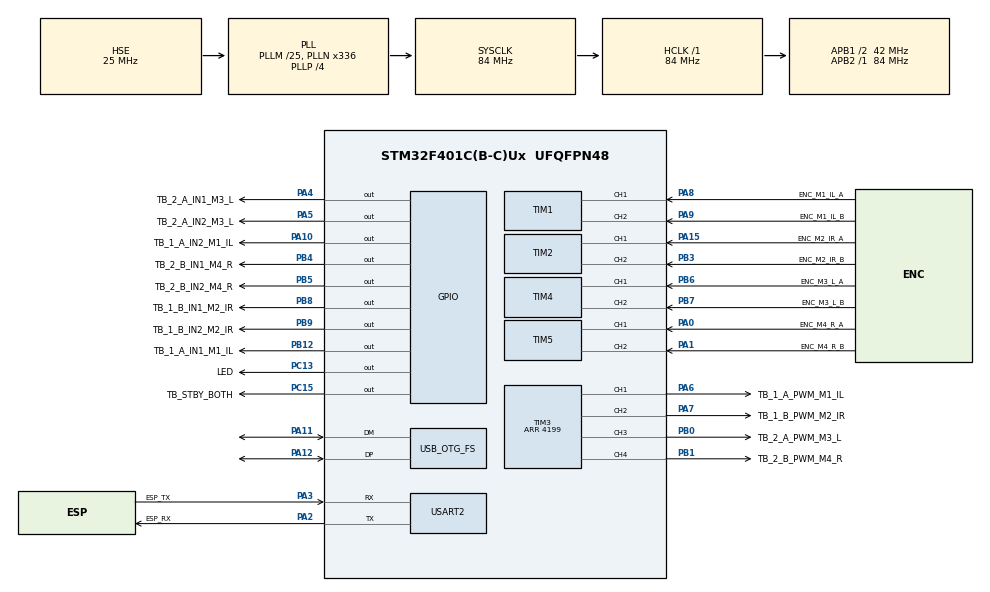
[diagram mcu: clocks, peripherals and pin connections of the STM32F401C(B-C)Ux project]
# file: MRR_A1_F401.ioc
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Dma.Request0=USART2_RX
Dma.Request1=USART2_TX
Dma.USART2_RX.0.Direction=DMA_PERIPH_TO_MEMORY
Dma.USART2_RX.0.FIFOMode=DMA_FIFOMODE_DISABLE
Dma.USART2_RX.0.Instance=DMA1_Stream5
Dma.USART2_RX.0.MemDataAlignment=DMA_MDATAALIGN_BYTE
Dma.USART2_RX.0.MemInc=DMA_MINC_ENABLE
Dma.USART2_RX.0.Mode=DMA_CIRCULAR
Dma.USART2_RX.0.PeriphDataAlignment=DMA_PDATAALIGN_BYTE
Dma.USART2_RX.0.PeriphInc=DMA_PINC_DISABLE
Dma.USART2_RX.0.Priority=DMA_PRIORITY_LOW
Dma.USART2_TX.1.Direction=DMA_MEMORY_TO_PERIPH
Dma.USART2_TX.1.FIFOMode=DMA_FIFOMODE_DISABLE
Dma.USART2_TX.1.Instance=DMA1_Stream6
Dma.USART2_TX.1.MemDataAlignment=DMA_MDATAALIGN_BYTE
Dma.USART2_TX.1.MemInc=DMA_MINC_ENABLE
Dma.USART2_TX.1.Mode=DMA_NORMAL
Dma.USART2_TX.1.PeriphDataAlignment=DMA_PDATAALIGN_BYTE
Dma.USART2_TX.1.PeriphInc=DMA_PINC_DISABLE
Dma.USART2_TX.1.Priority=DMA_PRIORITY_LOW
Mcu.Family=STM32F4
Mcu.Name=STM32F401C(B-C)Ux
Mcu.Package=UFQFPN48
NVIC.DMA1_Stream5_IRQn=true\:2\:0\:true\:false\:true\:false\:true\:true
NVIC.DMA1_Stream6_IRQn=true\:2\:0\:true\:false\:true\:false\:true\:true
NVIC.OTG_FS_IRQn=true\:3\:0\:true\:false\:true\:true\:true\:true
NVIC.PriorityGroup=NVIC_PRIORITYGROUP_4
NVIC.TIM1_UP_TIM10_IRQn=true\:1\:0\:true\:false\:true\:true\:true\:true
NVIC.USART2_IRQn=true\:2\:0\:true\:false\:true\:false\:true\:true
PA0-WKUP.GPIO_Label=ENC_M4_R_A
PA0-WKUP.GPIO_PuPd=GPIO_PULLUP
PA0-WKUP.Signal=S_TIM5_CH1
PA1.GPIO_Label=ENC_M4_R_B
PA1.GPIO_PuPd=GPIO_PULLUP
PA1.Signal=S_TIM5_CH2
PA10.GPIO_Label=TB_1_A_IN2_M1_IL
PA10.Signal=GPIO_Output
PA11.Mode=Device_Only
PA11.Signal=USB_OTG_FS_DM
PA12.Mode=Device_Only
PA12.Signal=USB_OTG_FS_DP
PA13.Mode=Serial_Wire
PA13.Signal=SYS_JTMS-SWDIO
PA14.Mode=Serial_Wire
PA14.Signal=SYS_JTCK-SWCLK
PA15.GPIO_Label=ENC_M2_IR_A
PA15.GPIO_PuPd=GPIO_PULLUP
PA15.Signal=S_TIM2_CH1_ETR
PA2.GPIO_Label=ESP_RX
PA2.Mode=Asynchronous
PA2.Signal=USART2_TX
PA3.GPIO_Label=ESP_TX
PA3.GPIO_PuPd=GPIO_PULLUP
PA3.Mode=Asynchronous
PA3.Signal=USART2_RX
PA4.GPIO_Label=TB_2_A_IN1_M3_L
PA4.Signal=GPIO_Output
PA5.GPIO_Label=TB_2_A_IN2_M3_L
PA5.Signal=GPIO_Output
PA6.GPIO_Label=TB_1_A_PWM_M1_IL
PA6.Signal=S_TIM3_CH1
PA7.GPIO_Label=TB_1_B_PWM_M2_IR
PA7.Signal=S_TIM3_CH2
PA8.GPIO_Label=ENC_M1_IL_A
PA8.GPIO_PuPd=GPIO_PULLUP
PA8.Signal=S_TIM1_CH1
PA9.GPIO_Label=ENC_M1_IL_B
PA9.GPIO_PuPd=GPIO_PULLUP
PA9.Signal=S_TIM1_CH2
PB0.GPIO_Label=TB_2_A_PWM_M3_L
PB0.Signal=S_TIM3_CH3
PB1.GPIO_Label=TB_2_B_PWM_M4_R
PB1.Signal=S_TIM3_CH4
PB12.GPIO_Label=TB_1_A_IN1_M1_IL
PB12.Signal=GPIO_Output
PB3.GPIO_Label=ENC_M2_IR_B
PB3.GPIO_PuPd=GPIO_PULLUP
PB3.Signal=S_TIM2_CH2
PB4.GPIO_Label=TB_2_B_IN1_M4_R
PB4.Signal=GPIO_Output
PB5.GPIO_Label=TB_2_B_IN2_M4_R
PB5.Signal=GPIO_Output
PB6.GPIO_Label=ENC_M3_L_A
PB6.GPIO_PuPd=GPIO_PULLUP
PB6.Signal=S_TIM4_CH1
PB7.GPIO_Label=ENC_M3_L_B
PB7.GPIO_PuPd=GPIO_PULLUP
PB7.Signal=S_TIM4_CH2
PB8.GPIO_Label=TB_1_B_IN1_M2_IR
PB8.Signal=GPIO_Output
PB9.GPIO_Label=TB_1_B_IN2_M2_IR
PB9.Signal=GPIO_Output
PC13-ANTI_TAMP.GPIO_Label=LED
PC13-ANTI_TAMP.Signal=GPIO_Output
PC15-OSC32_OUT.GPIO_Label=TB_STBY_BOTH
PC15-OSC32_OUT.Signal=GPIO_Output
PH0\ -\ OSC_IN.Mode=HSE-External-Oscillator
PH0\ -\ OSC_IN.Signal=RCC_OSC_IN
PH1\ -\ OSC_OUT.Mode=HSE-External-Oscillator
PH1\ -\ OSC_OUT.Signal=RCC_OSC_OUT
ProjectManager.HeapSize=0x400
ProjectManager.StackSize=0x1000
ProjectManager.TargetToolchain=CMake
RCC.48MHZClocksFreq_Value=48000000
RCC.AHBFreq_Value=84000000
RCC.APB1CLKDivider=RCC_HCLK_DIV2
RCC.APB1Freq_Value=42000000
RCC.APB1TimFreq_Value=84000000
RCC.APB2Freq_Value=84000000
RCC.APB2TimFreq_Value=84000000
RCC.CortexFreq_Value=84000000
RCC.HCLKFreq_Value=84000000
RCC.HSE_VALUE=25000000
RCC.HSI_VALUE=16000000
RCC.LSE_VALUE=32768
RCC.PLLM=25
RCC.PLLN=336
RCC.PLLP=RCC_PLLP_DIV4
RCC.PLLQ=7
RCC.SYSCLKFreq_VALUE=84000000
RCC.SYSCLKSource=RCC_SYSCLKSOURCE_PLLCLK
RCC.VCOOutputFreq_Value=336000000
SH.S_TIM1_CH1.0=TIM1_CH1,Encoder_Interface
SH.S_TIM1_CH2.0=TIM1_CH2,Encoder_Interface
SH.S_TIM2_CH1_ETR.0=TIM2_CH1,Encoder_Interface
SH.S_TIM2_CH2.0=TIM2_CH2,Encoder_Interface
SH.S_TIM3_CH1.0=TIM3_CH1,PWM Generation1 CH1
SH.S_TIM3_CH2.0=TIM3_CH2,PWM Generation2 CH2
SH.S_TIM3_CH3.0=TIM3_CH3,PWM Generation3 CH3
SH.S_TIM3_CH4.0=TIM3_CH4,PWM Generation4 CH4
SH.S_TIM4_CH1.0=TIM4_CH1,Encoder_Interface
SH.S_TIM4_CH2.0=TIM4_CH2,Encoder_Interface
SH.S_TIM5_CH1.0=TIM5_CH1,Encoder_Interface
SH.S_TIM5_CH2.0=TIM5_CH2,Encoder_Interface
TIM1.EncoderMode=TIM_ENCODERMODE_TI12
TIM1.IC1Filter=10
TIM1.IC2Filter=10
TIM10.AutoReloadPreload=TIM_AUTORELOAD_PRELOAD_ENABLE
TIM10.Period=999
TIM10.Prescaler=83
TIM2.EncoderMode=TIM_ENCODERMODE_TI12
TIM2.IC1Filter=10
TIM2.IC2Filter=10
TIM3.AutoReloadPreload=TIM_AUTORELOAD_PRELOAD_ENABLE
TIM3.Channel-PWM\ Generation1\ CH1=TIM_CHANNEL_1
TIM3.Channel-PWM\ Generation2\ CH2=TIM_CHANNEL_2
TIM3.Channel-PWM\ Generation3\ CH3=TIM_CHANNEL_3
TIM3.Channel-PWM\ Generation4\ CH4=TIM_CHANNEL_4
TIM3.Period=4199
TIM4.EncoderMode=TIM_ENCODERMODE_TI12
TIM4.IC1Filter=10
TIM4.IC2Filter=10
TIM5.EncoderMode=TIM_ENCODERMODE_TI12
TIM5.IC1Filter=10
TIM5.IC2Filter=10
USART2.VirtualMode=VM_ASYNC
USB_DEVICE.CLASS_NAME_FS=CDC
USB_DEVICE.VirtualMode=Cdc
USB_DEVICE.VirtualModeFS=Cdc_FS
USB_OTG_FS.VirtualMode=Device_Only
VP_TIM10_VS_ClockSourceINT.Mode=Enable_Timer
VP_USB_DEVICE_VS_USB_DEVICE_CDC_FS.Mode=CDC_FS
board=custom

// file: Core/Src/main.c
/* USER CODE BEGIN Header */
/**
  ******************************************************************************
  * @file           : main.c
  * @brief          : Main program body
  ******************************************************************************
  * @attention
  *
  * Copyright (c) 2026 STMicroelectronics.
  * All rights reserved.
  *
  * This software is licensed under terms that can be found in the LICENSE file
  * in the root directory of this software component.
  * If no LICENSE file comes with this software, it is provided AS-IS.
  *
  ******************************************************************************
  */
/* USER CODE END Header */
#include "main.h"
#include "dma.h"
#include "tim.h"
#include "usart.h"
#include "usb_device.h"
#include "gpio.h"

/* USER CODE BEGIN Includes */
#include "bootloader.h"
#include "app.h"
/* USER CODE END Includes */

void SystemClock_Config(void);

int main(void)
{

  /* USER CODE BEGIN 1 */
  Bootloader_JumpIfRequested();   /* must stay first: PC asked for DFU */

  /* USER CODE END 1 */

  /* MCU Configuration--------------------------------------------------------*/

  /* Reset of all peripherals, Initializes the Flash interface and the Systick. */
  HAL_Init();

  /* Configure the system clock */
  SystemClock_Config();

  /* Initialize all configured peripherals */
  MX_GPIO_Init();
  MX_DMA_Init();
  MX_TIM1_Init();
  MX_TIM2_Init();
  MX_TIM3_Init();
  MX_TIM4_Init();
  MX_TIM5_Init();
  MX_USART2_UART_Init();
  MX_TIM10_Init();
  MX_USB_DEVICE_Init();
  /* USER CODE BEGIN 2 */
  App_Init();

  /* USER CODE END 2 */

  /* Infinite loop */
  while (1)
  {

    /* USER CODE BEGIN 3 */
    App_MainLoop();
    Bootloader_Service();
  }
  /* USER CODE END 3 */
}

void SystemClock_Config(void)
{
  RCC_OscInitTypeDef RCC_OscInitStruct = {0};
  RCC_ClkInitTypeDef RCC_ClkInitStruct = {0};

  /** Configure the main internal regulator output voltage
  */
  __HAL_RCC_PWR_CLK_ENABLE();
  __HAL_PWR_VOLTAGESCALING_CONFIG(PWR_REGULATOR_VOLTAGE_SCALE2);

  /** Initializes the RCC Oscillators according to the specified parameters
  * in the RCC_OscInitTypeDef structure.
  */
  RCC_OscInitStruct.OscillatorType = RCC_OSCILLATORTYPE_HSE;
  RCC_OscInitStruct.HSEState = RCC_HSE_ON;
  RCC_OscInitStruct.PLL.PLLState = RCC_PLL_ON;
  RCC_OscInitStruct.PLL.PLLSource = RCC_PLLSOURCE_HSE;
  RCC_OscInitStruct.PLL.PLLM = 25;
  RCC_OscInitStruct.PLL.PLLN = 336;
  RCC_OscInitStruct.PLL.PLLP = RCC_PLLP_DIV4;
  RCC_OscInitStruct.PLL.PLLQ = 7;
  if (HAL_RCC_OscConfig(&RCC_OscInitStruct) != HAL_OK)
  {
    Error_Handler();
  }

  /** Initializes the CPU, AHB and APB buses clocks
  */
  RCC_ClkInitStruct.ClockType = RCC_CLOCKTYPE_HCLK|RCC_CLOCKTYPE_SYSCLK
                              |RCC_CLOCKTYPE_PCLK1|RCC_CLOCKTYPE_PCLK2;
  RCC_ClkInitStruct.SYSCLKSource = RCC_SYSCLKSOURCE_PLLCLK;
  RCC_ClkInitStruct.AHBCLKDivider = RCC_SYSCLK_DIV1;
  RCC_ClkInitStruct.APB1CLKDivider = RCC_HCLK_DIV2;
  RCC_ClkInitStruct.APB2CLKDivider = RCC_HCLK_DIV1;

  if (HAL_RCC_ClockConfig(&RCC_ClkInitStruct, FLASH_LATENCY_2) != HAL_OK)
  {
    Error_Handler();
  }
}

void Error_Handler(void)
{
  __disable_irq();
  while (1)
  {
  }
}
